AUTOSAR XML (schema 4-0-3)
package /ComponentTypes
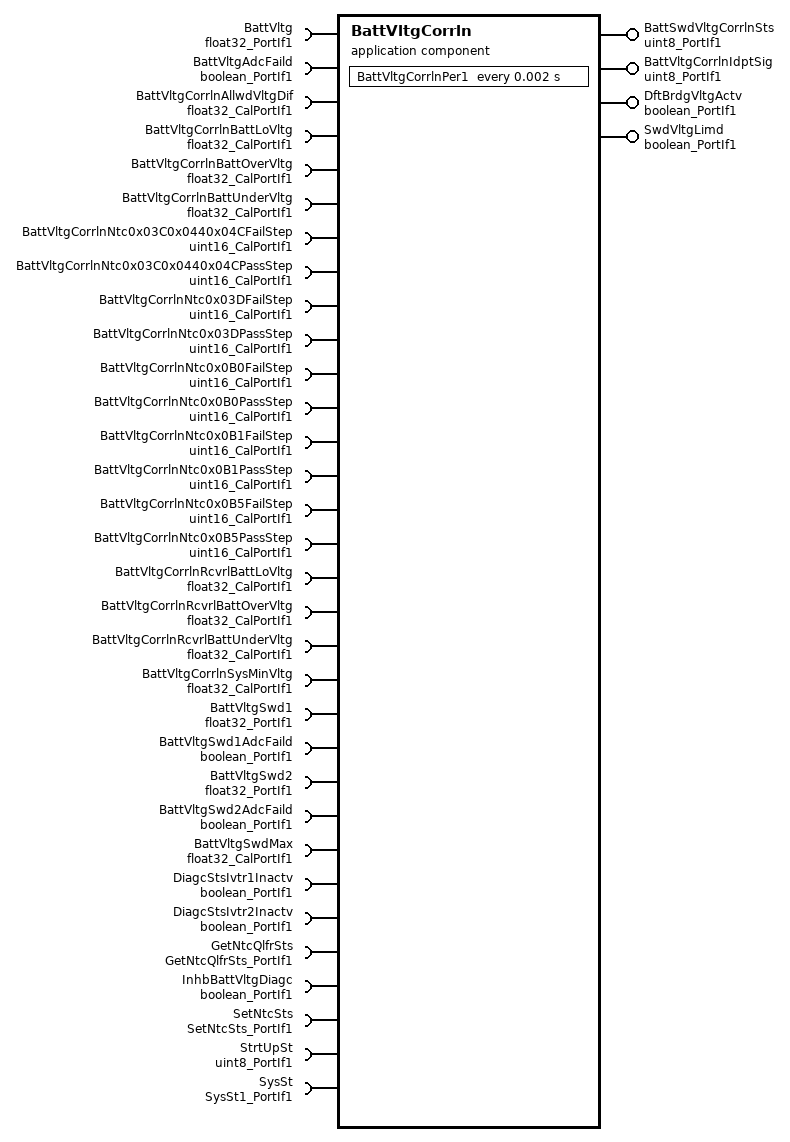
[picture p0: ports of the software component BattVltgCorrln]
  application sw component type BattVltgCorrln
    4 x provide port:
      BattSwdVltgCorrlnSts: nonqueued-sender-com-spec{data-element=Val, init-value=7}, provided-interface=uint8_PortIf1
      BattVltgCorrlnIdptSig: nonqueued-sender-com-spec{data-element=Val, init-value=3}, provided-interface=uint8_PortIf1
      DftBrdgVltgActv: nonqueued-sender-com-spec{data-element=Logl, init-value=0}, provided-interface=boolean_PortIf1
      SwdVltgLimd: nonqueued-sender-com-spec{data-element=Logl, init-value=0}, provided-interface=boolean_PortIf1
    32 x require port:
      BattVltg: nonqueued-receiver-com-spec{data-element=Val, filter=data-filter-type=ALWAYS, init-value=0}, required-interface=float32_PortIf1
      BattVltgAdcFaild: nonqueued-receiver-com-spec{data-element=Logl, filter=data-filter-type=ALWAYS, init-value=0}, required-interface=boolean_PortIf1
      BattVltgCorrlnAllwdVltgDif: parameter-require-com-spec{init-value=0.73, parameter=Val}, required-interface=float32_CalPortIf1
      BattVltgCorrlnBattLoVltg: parameter-require-com-spec{init-value=10, parameter=Val}, required-interface=float32_CalPortIf1
      BattVltgCorrlnBattOverVltg: parameter-require-com-spec{init-value=16, parameter=Val}, required-interface=float32_CalPortIf1
      BattVltgCorrlnBattUnderVltg: parameter-require-com-spec{init-value=9, parameter=Val}, required-interface=float32_CalPortIf1
      BattVltgCorrlnNtc0x03C0x0440x04CFailStep: parameter-require-com-spec{init-value=410, parameter=Val}, required-interface=uint16_CalPortIf1
      BattVltgCorrlnNtc0x03C0x0440x04CPassStep: parameter-require-com-spec{init-value=272, parameter=Val}, required-interface=uint16_CalPortIf1
      BattVltgCorrlnNtc0x03DFailStep: parameter-require-com-spec{init-value=410, parameter=Val}, required-interface=uint16_CalPortIf1
      BattVltgCorrlnNtc0x03DPassStep: parameter-require-com-spec{init-value=272, parameter=Val}, required-interface=uint16_CalPortIf1
      BattVltgCorrlnNtc0x0B0FailStep: parameter-require-com-spec{init-value=327, parameter=Val}, required-interface=uint16_CalPortIf1
      BattVltgCorrlnNtc0x0B0PassStep: parameter-require-com-spec{init-value=327, parameter=Val}, required-interface=uint16_CalPortIf1
      BattVltgCorrlnNtc0x0B1FailStep: parameter-require-com-spec{init-value=327, parameter=Val}, required-interface=uint16_CalPortIf1
      BattVltgCorrlnNtc0x0B1PassStep: parameter-require-com-spec{init-value=327, parameter=Val}, required-interface=uint16_CalPortIf1
      BattVltgCorrlnNtc0x0B5FailStep: parameter-require-com-spec{init-value=327, parameter=Val}, required-interface=uint16_CalPortIf1
      BattVltgCorrlnNtc0x0B5PassStep: parameter-require-com-spec{init-value=327, parameter=Val}, required-interface=uint16_CalPortIf1
      BattVltgCorrlnRcvrlBattLoVltg: parameter-require-com-spec{init-value=10.5, parameter=Val}, required-interface=float32_CalPortIf1
      BattVltgCorrlnRcvrlBattOverVltg: parameter-require-com-spec{init-value=15.5, parameter=Val}, required-interface=float32_CalPortIf1
      BattVltgCorrlnRcvrlBattUnderVltg: parameter-require-com-spec{init-value=9.5, parameter=Val}, required-interface=float32_CalPortIf1
      BattVltgCorrlnSysMinVltg: parameter-require-com-spec{init-value=6, parameter=Val}, required-interface=float32_CalPortIf1
      BattVltgSwd1: nonqueued-receiver-com-spec{data-element=Val, filter=data-filter-type=ALWAYS, init-value=0}, required-interface=float32_PortIf1
      BattVltgSwd1AdcFaild: nonqueued-receiver-com-spec{data-element=Logl, filter=data-filter-type=ALWAYS, init-value=0}, required-interface=boolean_PortIf1
      BattVltgSwd2: nonqueued-receiver-com-spec{data-element=Val, filter=data-filter-type=ALWAYS, init-value=0}, required-interface=float32_PortIf1
      BattVltgSwd2AdcFaild: nonqueued-receiver-com-spec{data-element=Logl, filter=data-filter-type=ALWAYS, init-value=0}, required-interface=boolean_PortIf1
      BattVltgSwdMax: parameter-require-com-spec{init-value=16, parameter=Val}, required-interface=float32_CalPortIf1
      DiagcStsIvtr1Inactv: nonqueued-receiver-com-spec{data-element=Logl, filter=data-filter-type=ALWAYS, init-value=0}, required-interface=boolean_PortIf1
      DiagcStsIvtr2Inactv: nonqueued-receiver-com-spec{data-element=Logl, filter=data-filter-type=ALWAYS, init-value=0}, required-interface=boolean_PortIf1
      GetNtcQlfrSts: required-interface=GetNtcQlfrSts_PortIf1
      InhbBattVltgDiagc: nonqueued-receiver-com-spec{data-element=Logl, filter=data-filter-type=ALWAYS, init-value=0}, required-interface=boolean_PortIf1
      SetNtcSts: required-interface=SetNtcSts_PortIf1
      StrtUpSt: nonqueued-receiver-com-spec{data-element=Val, filter=data-filter-type=ALWAYS, init-value=0}, required-interface=uint8_PortIf1
      SysSt: nonqueued-receiver-com-spec{data-element=Val, filter=data-filter-type=ALWAYS, init-value=3}, required-interface=SysSt1_PortIf1
    behavior BattVltgCorrln_InternalBehavior: data-type-mapping=Nexteer
      ar-typed-per-instance-memorys:
        10 x data, all with sw-calibration-access=READ-ONLY:
          dBattVltgCorrlnBattVltgOk: type=uint8
          dBattVltgCorrlnBattVltgRngOk: type=uint8
          dBattVltgCorrlnBattVltgSwd1Ok: type=uint8
          dBattVltgCorrlnBattVltgSwd1RngOk: type=uint8
          dBattVltgCorrlnBattVltgSwd2Ok: type=uint8
          dBattVltgCorrlnBattVltgSwd2RngOk: type=uint8
          dBattVltgCorrlnNtc0x03CQlfrSts: type=SigQlfr1
          dBattVltgCorrlnNtc0x03DQlfrSts: type=SigQlfr1
          dBattVltgCorrlnNtc0x044QlfrSts: type=SigQlfr1
          dBattVltgCorrlnNtc0x04CQlfrSts: type=SigQlfr1
      timing event TMT_BattVltgCorrlnPer1: start-on-event=BattVltgCorrlnPer1, period=0.002
      runnable BattVltgCorrlnPer1
        data-receive-point-by-arguments:
          11 x access:
            REC_BattVltg_Val: accessed-variable=BattVltg.Val
            REC_BattVltgAdcFaild_Logl: accessed-variable=BattVltgAdcFaild.Logl
            REC_BattVltgSwd1_Val: accessed-variable=BattVltgSwd1.Val
            REC_BattVltgSwd1AdcFaild_Logl: accessed-variable=BattVltgSwd1AdcFaild.Logl
            REC_BattVltgSwd2_Val: accessed-variable=BattVltgSwd2.Val
            REC_BattVltgSwd2AdcFaild_Logl: accessed-variable=BattVltgSwd2AdcFaild.Logl
            REC_DiagcStsIvtr1Inactv_Logl: accessed-variable=DiagcStsIvtr1Inactv.Logl
            REC_DiagcStsIvtr2Inactv_Logl: accessed-variable=DiagcStsIvtr2Inactv.Logl
            REC_InhbBattVltgDiagc_Logl: accessed-variable=InhbBattVltgDiagc.Logl
            REC_StrtUpSt_Val: accessed-variable=StrtUpSt.Val
            REC_SysSt_Val: accessed-variable=SysSt.Val
        data-send-points:
          5 x access:
            SEND_BattSwdVltgCorrlnSts_Val: accessed-variable=BattSwdVltgCorrlnSts.Val
            SEND_BattSwdVltgCorrlnSts_Val_1: accessed-variable=BattSwdVltgCorrlnSts.Val
            SEND_BattVltgCorrlnIdptSig_Val: accessed-variable=BattVltgCorrlnIdptSig.Val
            SEND_DftBrdgVltgActv_Logl: accessed-variable=DftBrdgVltgActv.Logl
            SEND_SwdVltgLimd_Logl: accessed-variable=SwdVltgLimd.Logl
        sync call SC_GetNtcQlfrSts_Oper: operation=GetNtcQlfrSts.Oper, timeout=0
        sync call SC_SetNtcSts_Oper: operation=SetNtcSts.Oper, timeout=0
  swc implementation BattVltgCorrln_Implementation: behavior=BattVltgCorrln_InternalBehavior
    code-descriptors:
      code Default: artifact-descriptors=autosar-engineering-object={short-label=Default, category=SWSRC}
